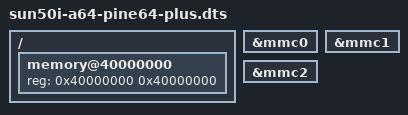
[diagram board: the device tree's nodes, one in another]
// SPDX-License-Identifier: GPL-2.0

#include <arm64/allwinner/sun50i-a64-pine64-plus.dts>
/{
       memory@40000000 {
               device_type = "memory";
               reg = <0x40000000 0x40000000>; /* 1 GB */
       };
};
&mmc0 { /* SD */
};
&mmc1 { /* PIO */
};
&mmc2 { /* eMMC */
       status = "ok";
};
